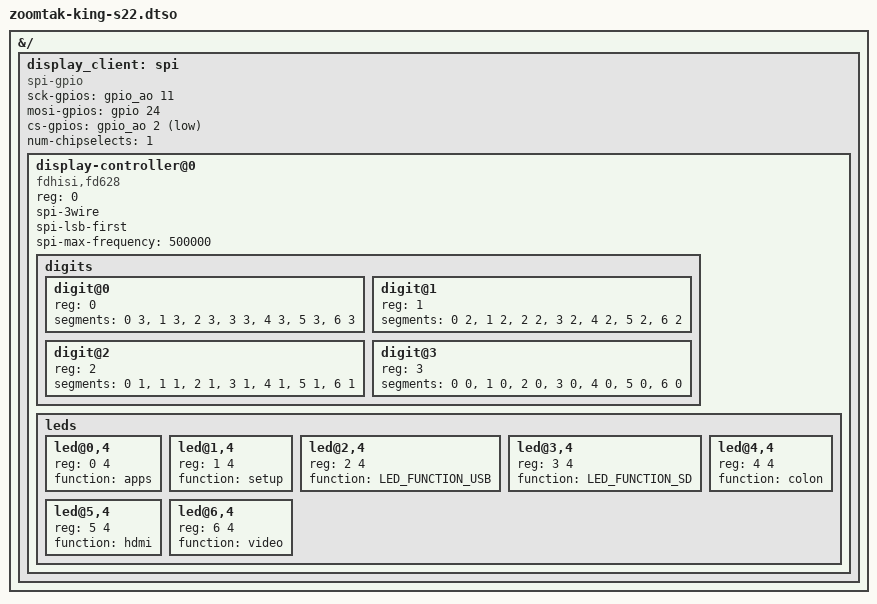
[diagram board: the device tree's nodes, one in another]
/dts-v1/;
/plugin/;

#include <dt-bindings/gpio/gpio.h>
#include <dt-bindings/leds/common.h>

&{/} {

	display_client: spi {
		#address-cells = <1>;
		#size-cells = <0>;
		compatible = "spi-gpio";
		sck-gpios = <&gpio_ao 11 GPIO_ACTIVE_HIGH>;
		mosi-gpios = <&gpio 24 GPIO_ACTIVE_HIGH>;
		cs-gpios = <&gpio_ao 2 GPIO_ACTIVE_LOW>;
		num-chipselects = <1>;

		display-controller@0 {
			compatible = "fdhisi,fd628", "titanmec,tm1628";
			reg = <0>;
			spi-3wire;
			spi-lsb-first;
			spi-max-frequency = <500000>;

			digits {
				#address-cells = <1>;
				#size-cells = <0>;
				digit@0 {
					reg = <0>;
					segments = <0 3>,
						   <1 3>,
						   <2 3>,
						   <3 3>,
						   <4 3>,
						   <5 3>,
						   <6 3>;
				};
				digit@1 {
					reg = <1>;
					segments = <0 2>,
						   <1 2>,
						   <2 2>,
						   <3 2>,
						   <4 2>,
						   <5 2>,
						   <6 2>;
				};
				digit@2 {
					reg = <2>;
					segments = <0 1>,
						   <1 1>,
						   <2 1>,
						   <3 1>,
						   <4 1>,
						   <5 1>,
						   <6 1>;
				};
				digit@3 {
					reg = <3>;
					segments = <0 0>,
						   <1 0>,
						   <2 0>,
						   <3 0>,
						   <4 0>,
						   <5 0>,
						   <6 0>;
				};
			};

			leds {
				#address-cells = <2>;
				#size-cells = <0>;
				led@0,4 {
					reg = <0 4>;
					function = "apps";
				};
				led@1,4 {
					reg = <1 4>;
					function = "setup";
				};
				led@2,4 {
					reg = <2 4>;
					function = LED_FUNCTION_USB;
				};
				led@3,4 {
					reg = <3 4>;
					function = LED_FUNCTION_SD;
				};
				led@4,4 {
					reg = <4 4>;
					function = "colon";
				};
				led@5,4 {
					reg = <5 4>;
					function = "hdmi";
				};
				led@6,4 {
					reg = <6 4>;
					function = "video";
				};
			};
		};
	};
};
